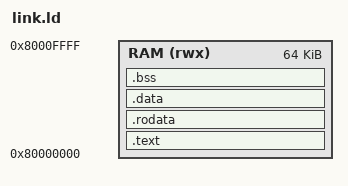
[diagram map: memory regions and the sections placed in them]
ENTRY(_start)

MEMORY {
  RAM (rwx) : ORIGIN = 0x80000000, LENGTH = 64K
}

SECTIONS {
  .text : { *(.text .text.*) } > RAM
  .rodata : { *(.rodata .rodata.*) } > RAM
  .data : { *(.data .data.*) } > RAM
  .bss : {
    __bss_start = .;
    *(.bss .bss.* COMMON)
    __bss_end = .;
  } > RAM
}

  /* Define stack at the top of RAM */
PROVIDE(__stack_top = ORIGIN(RAM) + LENGTH(RAM));
